# ET6801 register map
Vendor: ETMCU Inc.; File version: v0.0.1
CPU: CM7 r2p1, little endian, MPU, FPU, I-cache, D-cache, ITCM, DTCM, 4 interrupt priority bits
Registers are 32-bit, read-write, reset 0x0 unless marked. A register's access mark holds for its fields unless they carry their own. Offsets are from the block's base; [hi:lo] are bit positions; {n}, {i} and the like mark numbered series; 'fields as' and 'values as' point back to an identical list.

## ACMP0 — Provide an overview of the purpose and functionality of the peripheral: cmpc_cfg
Base 0x40104000
Same registers: ACMP{n} {0x40104000+0x1000*n} (n=1..10)
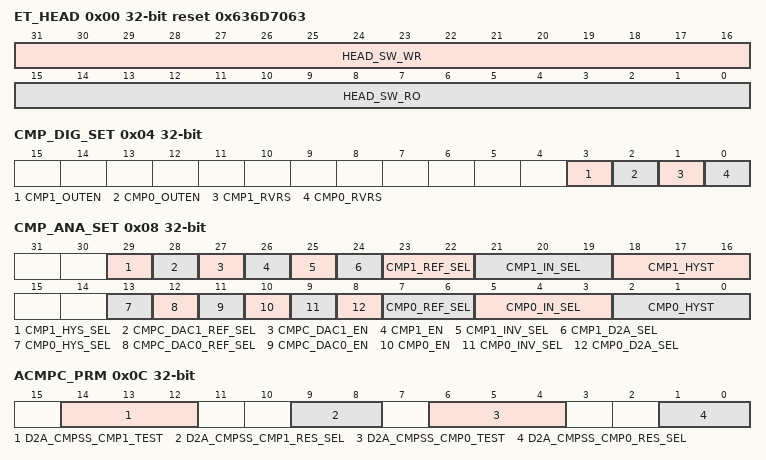
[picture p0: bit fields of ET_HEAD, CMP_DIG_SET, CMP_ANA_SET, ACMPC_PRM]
0x00 ET_HEAD reset 0x636D7063
  [31:16] HEAD_SW_WR — 软件测试读写寄存器，硬件无访问
  [15:0] HEAD_SW_RO ro — 软件只读上报寄存器，硬件无访问，cmpc的ASICII 码表示
0x04 CMP_DIG_SET
  [3] CMP1_OUTEN — 屏蔽比较器1同步输出寄存器
  [2] CMP0_OUTEN — 屏蔽比较器0同步输出寄存器
  [1] CMP1_RVRS — 比较器1输出取反寄存器
  [0] CMP0_RVRS — 比较器0输出取反寄存器
0x08 CMP_ANA_SET
  [29] CMP1_HYS_SEL — CMPSS的cmp1迟滞反向选择0：下降沿迟滞1：上升沿迟滞
  [28] CMPC_DAC1_REF_SEL — CMPC的DAC1 reference源选择寄存器
  [27] CMPC_DAC1_EN — CMPC的DAC1使能信号
  [26] CMP1_EN — 模拟比较器1使能寄存器
  [25] CMP1_INV_SEL — CMP1的输出反向选择寄存器
  [24] CMP1_D2A_SEL — CMP1的DAC输出测试寄存器
  [23:22] CMP1_REF_SEL — CMP0的ref端接法选择寄存器
  [21:19] CMP1_IN_SEL — CMP0的in端接法选择寄存器
  [18:16] CMP1_HYST — CMP1的迟滞寄存器 'd0：0 'd1：7mV 'd2：14mV 'd3：23mV 'd4：36mV 'd5：43mV 'd6：52mV 'd7：62mV
  [13] CMP0_HYS_SEL — CMPSS的cmp0迟滞反向选择0：下降沿迟滞1：上升沿迟滞
  [12] CMPC_DAC0_REF_SEL — CMPC的DAC0 reference源选择寄存器
  [11] CMPC_DAC0_EN — CMPC的DAC0使能信号
  [10] CMP0_EN — 模拟比较器0使能寄存器
  [9] CMP0_INV_SEL — CMP0的输出反向选择寄存器
  [8] CMP0_D2A_SEL — CMP0的DAC输出测试寄存器
  [7:6] CMP0_REF_SEL — CMP0的ref端接法选择寄存器
  [5:3] CMP0_IN_SEL — CMP0的in端接法选择寄存器
  [2:0] CMP0_HYST — CMP0的迟滞寄存器 'd0：0 'd1：7mV 'd2：14mV 'd3：23mV 'd4：36mV 'd5：43mV 'd6：52mV 'd7：62mV
0x0C ACMPC_PRM
  [14:12] D2A_CMPSS_CMP1_TEST — cmp1测试档位选择
  [9:8] D2A_CMPSS_CMP1_RES_SEL — cmp1电阻负载档位选择
  [6:4] D2A_CMPSS_CMP0_TEST — cmp0测试档位选择
  [1:0] D2A_CMPSS_CMP0_RES_SEL — cmp0电阻负载档位选择
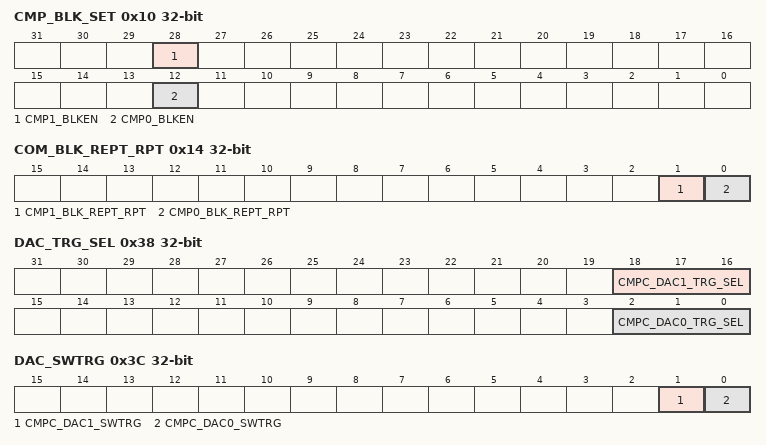
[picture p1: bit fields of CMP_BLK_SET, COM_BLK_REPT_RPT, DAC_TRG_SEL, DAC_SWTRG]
0x10 CMP_BLK_SET
  [28] CMP1_BLKEN — CMP1数字模块消隐使能寄存器
  [12] CMP0_BLKEN — CMP0数字模块消隐使能寄存器
0x14 COM_BLK_REPT_RPT
  [1] CMP1_BLK_REPT_RPT — CMP1数字模块消隐源重复告警，软件写1清。
  [0] CMP0_BLK_REPT_RPT — CMP0数字模块消隐源重复告警，软件写1清。
0x18 INT_MASK
  [5:0] CMPC_INT_MASK — 中断屏蔽信号
0x1C INT_EN
  [5:0] CMPC_INT_EN — 中断源使能信号
0x20 INT_FORCE_IND
  [5:0] CMPC_INT_FORCE_IND — 事件中断测试寄存器，自清0寄存器
0x24 INT_CLR
  [5:0] CMPC_INT_CLR — 中断清除寄存器，自清0寄存器
0x28 INT_RAW_RPT ro
  [5:0] CMPC_INT_RAW_RPT — CMPC发送结束事件原始中断寄存器
0x2C INT_STATUS_RPT ro
  [5:0] CMPC_INT_STATUS_RPT — CMPC发送结束事件中断状态寄存器
0x30 DAC0_TDAT
  [11:0] CMPC_DAC0_TDAT — DAC0发送数据寄存器
0x34 DAC1_TDAT
  [11:0] CMPC_DAC1_TDAT — DAC1发送数据寄存器
0x38 DAC_TRG_SEL
  [18:16] CMPC_DAC1_TRG_SEL — DAC1触发启动源选择寄存器 'd0: 触发启动源选择SW配置; 'd1 : 触发启动源选择stimer; 'd2 : 触发启动源选择eTimer; 'd3 : 触发启动源选择SuperPWM; 'd4 : 触发启动源选择tx down event; 'd5 : 未使用，接0; 'd6: 触发启动源选reference dac对应的比较器; 'd7 : 触发启动源选择DMA搬移完成;
  [2:0] CMPC_DAC0_TRG_SEL — DAC0触发启动源选择寄存器 'd0: 触发启动源选择SW配置; 'd1 : 触发启动源选择stimer; 'd2 : 触发启动源选择eTimer; 'd3 : 触发启动源选择SuperPWM; 'd4 : 触发启动源选择tx down event; 'd5 : 未使用，接0; 'd6: 触发启动源选reference dac对应的比较器; 'd7 : 触发启动源选择DMA搬移完成;
0x3C DAC_SWTRG
  [1] CMPC_DAC1_SWTRG — DAC1软件触发寄存器
  [0] CMPC_DAC0_SWTRG — DAC0软件触发寄存器
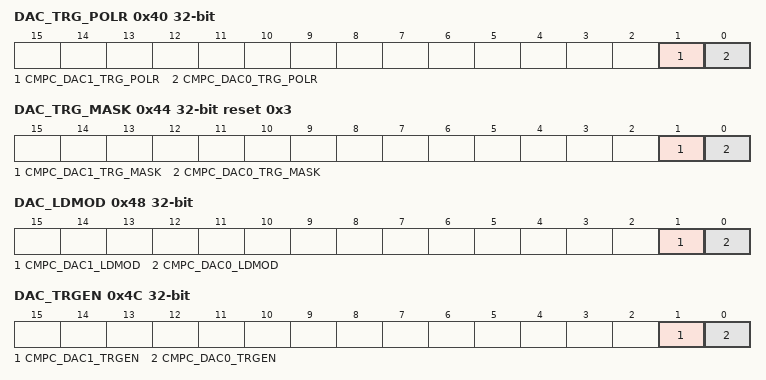
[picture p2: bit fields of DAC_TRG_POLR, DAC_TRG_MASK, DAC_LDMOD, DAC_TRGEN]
0x40 DAC_TRG_POLR
  [1] CMPC_DAC1_TRG_POLR — DAC1触发源极性取反寄存器
  [0] CMPC_DAC0_TRG_POLR — DAC0触发源极性取反寄存器
0x44 DAC_TRG_MASK reset 0x3
  [1] CMPC_DAC1_TRG_MASK — DAC1触发源屏蔽寄存器
  [0] CMPC_DAC0_TRG_MASK — DAC0触发源屏蔽寄存器
0x48 DAC_LDMOD
  [1] CMPC_DAC1_LDMOD — DAC1加载模式选择寄存器
  [0] CMPC_DAC0_LDMOD — DAC0加载模式选择寄存器
0x4C DAC_TRGEN
  [1] CMPC_DAC1_TRGEN — DAC1发波启动使能控制信号寄存器 0：DAC发波不使能； 1：DAC发波使能；
  [0] CMPC_DAC0_TRGEN — DAC0发波启动使能控制信号寄存器 0：DAC发波不使能； 1：DAC发波使能；
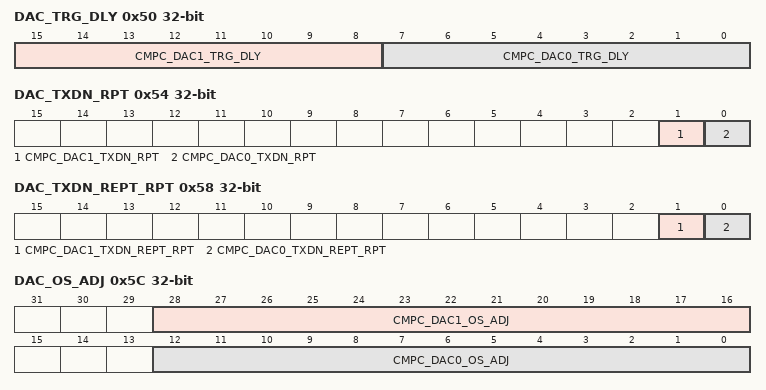
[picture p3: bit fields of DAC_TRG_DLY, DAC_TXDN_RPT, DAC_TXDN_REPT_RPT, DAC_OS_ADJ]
0x50 DAC_TRG_DLY
  [15:8] CMPC_DAC1_TRG_DLY — DAC1触发启动延迟寄存器
  [7:0] CMPC_DAC0_TRG_DLY — DAC0触发启动延迟寄存器
0x54 DAC_TXDN_RPT
  [1] CMPC_DAC1_TXDN_RPT — DAC1发波结束上报寄存器，软件写1清 注：在dac1_tdat_sel =1时，即数据源来源于dacc的输入端口时，内部的数据伴随时钟将常为高，该上报寄存器也一直为1。
  [0] CMPC_DAC0_TXDN_RPT — DAC0发波结束上报寄存器，软件写1清 注：在dac0_tdat_sel =1时，即数据源来源于dacc的输入端口时，内部的数据伴随时钟将常为高，该上报寄存器也一直为1。
0x58 DAC_TXDN_REPT_RPT
  [1] CMPC_DAC1_TXDN_REPT_RPT — DAC1发波结束重复上报告警，软件写1清 注：在dac1_tdat_sel =1时，即数据源来源于dacc的输入端口时，内部的数据伴随时钟将常为高，该上报寄存器也一直为1。
  [0] CMPC_DAC0_TXDN_REPT_RPT — DAC0发波结束重复上报告警，软件写1清 注：在dac0_tdat_sel =1时，即数据源来源于dacc的输入端口时，内部的数据伴随时钟将常为高，该上报寄存器也一直为1。
0x5C DAC_OS_ADJ
  [28:16] CMPC_DAC1_OS_ADJ — DAC1直流失配调整寄存器
  [12:0] CMPC_DAC0_OS_ADJ — DAC0直流失配调整寄存器
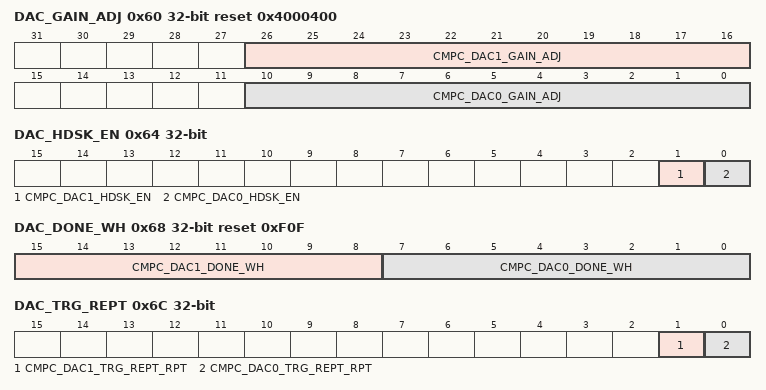
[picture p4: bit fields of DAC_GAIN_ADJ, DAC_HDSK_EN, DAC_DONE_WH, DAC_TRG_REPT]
0x60 DAC_GAIN_ADJ reset 0x4000400
  [26:16] CMPC_DAC1_GAIN_ADJ — DAC1增益误差调整寄存器
  [10:0] CMPC_DAC0_GAIN_ADJ — DAC0增益误差调整寄存器
0x64 DAC_HDSK_EN
  [1] CMPC_DAC1_HDSK_EN — DAC1 DMA握手模块使能寄存器
  [0] CMPC_DAC0_HDSK_EN — DAC0 DMA握手模块使能寄存器
0x68 DAC_DONE_WH reset 0xF0F
  [15:8] CMPC_DAC1_DONE_WH — DAC1发波结束事件脉冲扩展寄存器
  [7:0] CMPC_DAC0_DONE_WH — DAC0发波结束事件脉冲扩展寄存器
0x6C DAC_TRG_REPT
  [1] CMPC_DAC1_TRG_REPT_RPT — DAC1触发重复告警寄存器，软件写1清。
  [0] CMPC_DAC0_TRG_REPT_RPT — DAC0触发重复告警寄存器，软件写1清。
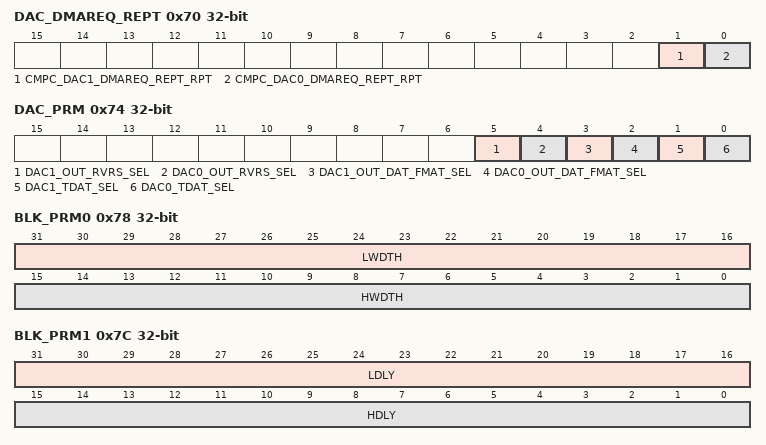
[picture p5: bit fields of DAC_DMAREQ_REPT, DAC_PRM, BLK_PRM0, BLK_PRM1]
0x70 DAC_DMAREQ_REPT
  [1] CMPC_DAC1_DMAREQ_REPT_RPT — DAC1 DMA握手模块请求脉冲重复告警，软件写1清。
  [0] CMPC_DAC0_DMAREQ_REPT_RPT — DAC0 DMA握手模块请求脉冲重复告警，软件写1清。
0x74 DAC_PRM
  [5] DAC1_OUT_RVRS_SEL — dac1输出数据反向选择 'd0:dac输出数据不反向，默认值； 'd1: dac输出数据反向；
  [4] DAC0_OUT_RVRS_SEL — dac0输出数据反向选择 'd0:dac输出数据不反向，默认值； 'd1: dac输出数据反向；
  [3] DAC1_OUT_DAT_FMAT_SEL — dac1输出数据格式选择 'd0:偏移码输出，默认值； 'd1:补码输出；
  [2] DAC0_OUT_DAT_FMAT_SEL — dac0输出数据格式选择 'd0:偏移码输出，默认值； 'd1:补码输出；
  [1] DAC1_TDAT_SEL — DAC发送数据寄存器 'd0: DAC选择从cfg_dac_tdat位域发送数据，默认值； 'd1:DAC选择从输入数据端口发送数据；
  [0] DAC0_TDAT_SEL — DAC发送数据寄存器 'd0: DAC选择从cfg_dac_tdat位域发送数据，默认值； 'd1:DAC选择从输入数据端口发送数据；
0x78 BLK_PRM0
  [31:16] LWDTH — CMP1数字模块Blanking窗口宽度寄存器
  [15:0] HWDTH — CMP0数字模块Blanking窗口宽度寄存器
0x7C BLK_PRM1
  [31:16] LDLY — CMP1数字模块Blanking延时大小寄存器
  [15:0] HDLY — CMP0数字模块Blanking延时大小寄存器
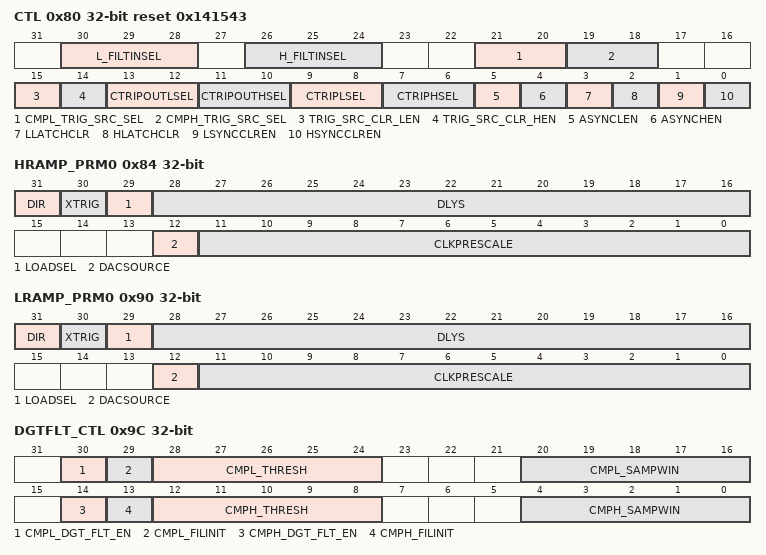
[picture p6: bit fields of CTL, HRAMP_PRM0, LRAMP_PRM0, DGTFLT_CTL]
0x80 CTL reset 0x141543
  [30:28] L_FILTINSEL — 低电平滤波器输入mux选择位。 'd0：选择低电平模拟比较器作为低电平滤波器的输入 'd1：选择外部信号cmpc_l_filtin[0]作为低电平滤波器的输入 'd2：选择外部信号cmpc_l _filtin[1]作为低电平滤波器的输入 ...... 'd7：选择外部信号cmpc_l_filtin[6]作为低电平滤波器的输入
  [26:24] H_FILTINSEL — 高电平滤波器输入mux选择位。 'd0：选择高电平模拟比较器作为高电平滤波器的输入 'd1：选择外部信号cmpc_h_filtin[0]作为高电平滤波器的输入 'd2：选择外部信号cmpc_h_filtin[1]作为高电平滤波器的输入 ...... 'd7：选择外部信号cmpc_h_filtin[6]作为高电平滤波器的输入
  [21:20] CMPL_TRIG_SRC_SEL — 低电平比较器trigger源选择。 'd0，'d1：同步比较器输出驱动ctripoutl 'd2：数字滤波器输出驱动ctripoutl 'd3：1'd0
  [19:18] CMPH_TRIG_SRC_SEL — 高电平比较器trigger源选择。 'd0，'d1：同步比较器输出驱动ctripouth 'd2：数字滤波器输出驱动ctripouth 'd3：1'd0
  [15] TRIG_SRC_CLR_LEN — 低电平比较器触发源是否清除锁存器。 'd0：低电平比较器触发源不清除锁存器； 'd1：低电平比较器触发源清除锁存器；
  [14] TRIG_SRC_CLR_HEN — 高电平比较器触发源是否清除锁存器。 'd0：高电平比较器触发源不清除锁存器； 'd1：高电平比较器触发源清除锁存器；
  [13:12] CTRIPOUTLSEL — 低电平比较器ctripoutl源选择。 'd0：异步比较器输出驱动ctripoutl 'd1：同步比较器输出驱动ctripoutl 'd2：数字滤波器输出驱动ctripoutl 'd3：数字滤波器锁存输出驱动ctripoutl
  [11:10] CTRIPOUTHSEL — 高电平比较器ctripouth源选择。 'd0：异步比较器输出驱动ctripouth 'd1：同步比较器输出驱动ctripouth 'd2：数字滤波器输出驱动ctripouth 'd3：数字滤波器锁存输出驱动ctripouth
  [9:8] CTRIPLSEL — 低电平比较器ctripl源选择。 'd0：异步比较器输出驱动ctripl 'd1：同步比较器输出驱动ctripl 'd2：数字滤波器输出驱动ctripl 'd3：数字滤波器锁存输出驱动ctripl
  [7:6] CTRIPHSEL — 高电平比较器ctriph源选择。 'd0：异步比较器输出驱动ctriph 'd1：同步比较器输出驱动ctriph 'd2：数字滤波器输出驱动ctriph 'd3：数字滤波器锁存输出驱动ctriph
  [5] ASYNCLEN — 低电平比较器异步路径启用。当ctriplsel=3或ctripoutlsel=3时，允许异步比较器输出流入带有锁存数字滤波器信号的OR门。 'd0：异步比较器输出不流入带有锁存数字滤波器信号的OR门 'd1：异步比较器输出流入带有锁存数字滤波器信号的OR门
  [4] ASYNCHEN — 高电平比较器异步路径启用。当ctriphsel=3或ctripouthsel=3时，允许异步比较器输出流入带有锁存数字滤波器信号的OR门。 'd0：异步比较器输出不流入带有锁存数字滤波器信号的OR门 'd1：异步比较器输出流入带有锁存数字滤波器信号的OR门
  [3] LLATCHCLR — 低电平比较器锁存器软件清除。 'd0:无效果； 'd1:清除低电平比较器锁存器；
  [2] HLATCHCLR — 高电平比较器锁存器软件清除。 'd0:无效果； 'd1:清除高电平比较器锁存器；
  [1] LSYNCCLREN — 低电平比较器消影信号清除。 'd0:清除消影信号； 'd1:消影信号保持；
  [0] HSYNCCLREN — 高电平比较器消影信号清除。 'd0:清除消影信号； 'd1:消影信号保持；
0x84 HRAMP_PRM0
  [31] DIR — ramp产生器方向控制 'd0：递减ramp； 'd1：递增ramp；
  [30] XTRIG — ramp产生器交叉trigger on配置 'd0：ramp产生器的trigger on选择外部触发源； 'd1：ramp产生器的trigger on选择另一路ramp产生器的trigger off触发源；
  [29] LOADSEL — ramp装载选择。决定当trig_off_po被触发时，rampsts是从rampmaxrefa还是rampmaxrefs更新。 'd0：从rampmaxrefa加载rampsts； 'd1：从rampmaxrefs加载rampsts；
  [28:16] DLYS — ramp延时值。
  [12] DACSOURCE — 高电平比较器DAC源选择。确定是从wag还是从ramp产生器输入到DAC。 'd0：从wag输入到DAC； 'd1：使能ramp产生器，从ramp产生器输入到DAC；
  [11:0] CLKPRESCALE — ramp时钟预分频。
0x88 HRAMP_PRM1
  [15:0] DECVALS — ramp递减步进值。
0x8C HRAMP_PRM2
  [15:0] MAXREFS — ramp最大参考值。支持通过DMA配置。
0x90 LRAMP_PRM0
  [31] DIR — ramp产生器方向控制 'd0：递减ramp； 'd1：递增ramp；
  [30] XTRIG — ramp产生器交叉trigger on配置 'd0：ramp产生器的trigger on选择外部触发源； 'd1：ramp产生器的trigger on选择另一路ramp产生器的trigger off触发源；
  [29] LOADSEL — ramp装载选择。决定当trig_off_po被触发时，rampsts是从rampmaxrefa还是rampmaxrefs更新。 'd0：从rampmaxrefa加载rampsts； 'd1：从rampmaxrefs加载rampsts；
  [28:16] DLYS — ramp延时值。
  [12] DACSOURCE — 低电平电平比较器DAC源选择。确定是从wag还是从ramp产生器输入到DAC。 'd0：从wag输入到DAC； 'd1：使能ramp产生器，从ramp产生器输入到DAC；
  [11:0] CLKPRESCALE — ramp时钟预分频。
0x94 LRAMP_PRM1
  [15:0] DECVALS — ramp递减步进值。
0x98 LRAMP_PRM2
  [15:0] MAXREFS — ramp最大参考值。支持通过DMA配置。
0x9C DGTFLT_CTL
  [30] CMPL_DGT_FLT_EN — 是否使能低电平比较器数字滤波器。
  [29] CMPL_FILINIT wo — 低电平比较器数字滤波器初始化。 'd0:无影响 'd1:将所有样本初始化为滤波器输入值
  [28:24] CMPL_THRESH — 低电平比较器数字滤波器多数投票阈值。为了使输出改变状态，必须在样本窗口内出现至少THRESH个相反状态的样本。
  [20:16] CMPL_SAMPWIN — 低电平比较器数字滤波器样本窗口大小。要监控的采样数为SAMPWIN+1。
  [14] CMPH_DGT_FLT_EN — 是否使能高电平比较器数字滤波器。
  [13] CMPH_FILINIT wo — 高电平比较器数字滤波器初始化。 'd0:无影响 'd1:将所有样本初始化为滤波器输入值
  [12:8] CMPH_THRESH — 高电平比较器数字滤波器多数投票阈值。为了使输出改变状态，必须在样本窗口内出现至少THRESH个相反状态的样本。
  [4:0] CMPH_SAMPWIN — 高电平比较器数字滤波器样本窗口大小。要监控的采样数为SAMPWIN+1。
0xA0 HDGTFLT_CLKCTL
  [23:0] CMPH_CLKPRESCALE — 高电平比较器数字滤波器采样时钟预刻度。采样之间的系统时钟数。
0xA4 LDGTFLT_CLKCTL
  [23:0] CMPL_CLKPRESCALE — 低电平比较器数字滤波器采样时钟预刻度。采样之间的系统时钟数。
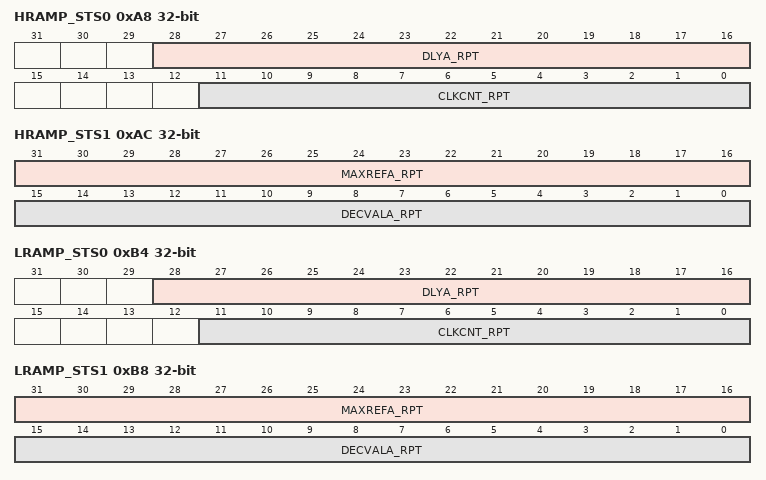
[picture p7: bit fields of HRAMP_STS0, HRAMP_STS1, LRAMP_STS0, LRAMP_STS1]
0xA8 HRAMP_STS0 ro
  [28:16] DLYA_RPT — ramp延时值计数器上报值。
  [11:0] CLKCNT_RPT — ramp时钟预分频计数器上报值。
0xAC HRAMP_STS1 ro
  [31:16] MAXREFA_RPT — rampsts的初始值内部影子寄存器上报。
  [15:0] DECVALA_RPT — ramp递减步进值上报。
0xB0 HRAMP_STS2 ro
  [15:0] STS_RPT — rampsts计数器上报值。
0xB4 LRAMP_STS0 ro
  fields as HRAMP_STS0
0xB8 LRAMP_STS1 ro
  fields as HRAMP_STS1
0xBC LRAMP_STS2 ro
  [15:0] STS_RPT — rampsts计数器上报值。
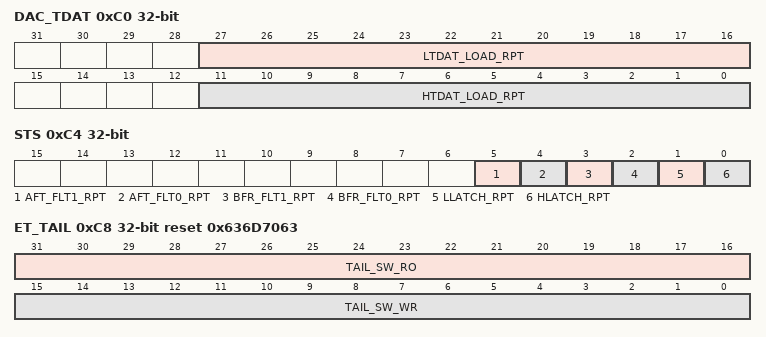
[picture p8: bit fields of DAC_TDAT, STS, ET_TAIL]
0xC0 DAC_TDAT ro
  [27:16] LTDAT_LOAD_RPT — cmp1 dac load数据上报
  [11:0] HTDAT_LOAD_RPT — cmp0 dac load数据上报
0xC4 STS ro
  [5] AFT_FLT1_RPT — 比较器0状态滤波后实时上报
  [4] AFT_FLT0_RPT — 比较器1状态滤波前实时上报
  [3] BFR_FLT1_RPT — 比较器0状态滤波后实时上报
  [2] BFR_FLT0_RPT — 比较器0状态滤波前实时上报
  [1] LLATCH_RPT — 低电平比较器锁存器输出上报
  [0] HLATCH_RPT — 高电平比较器锁存器输出上报
0xC8 ET_TAIL reset 0x636D7063
  [31:16] TAIL_SW_RO ro — 软件只读硬件上报寄存器
  [15:0] TAIL_SW_WR — 软件测试读写寄存器，硬件无访问
